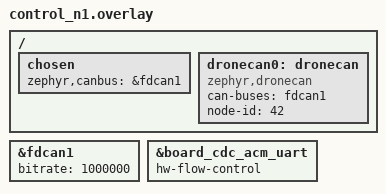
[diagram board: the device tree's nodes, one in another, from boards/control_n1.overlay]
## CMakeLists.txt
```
# SPDX-License-Identifier: Apache-2.0

cmake_minimum_required(VERSION 3.28.0)

# Use the module from this repository so the sample builds standalone.
list(APPEND ZEPHYR_EXTRA_MODULES ${CMAKE_CURRENT_LIST_DIR}/../..)

find_package(Zephyr REQUIRED HINTS $ENV{ZEPHYR_BASE})
project(dronecan_sample)

target_sources(app PRIVATE src/main.c)
```

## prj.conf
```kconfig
CONFIG_CAN=y
CONFIG_LOG=y
CONFIG_DRONECAN=y
CONFIG_DRONECAN_NODE_TABLE=y
CONFIG_DRONECAN_DNIA_SERVER=y
CONFIG_DRONECAN_LOG_LEVEL_DBG=y
```

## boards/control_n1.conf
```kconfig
# Console and logs on a USB CDC ACM port, using the USB device next stack.
# The board's own console is UART7, which needs a USB-serial adapter.
CONFIG_SERIAL=y
CONFIG_CONSOLE=y
CONFIG_UART_CONSOLE=y
CONFIG_UART_LINE_CTRL=y
CONFIG_USB_DEVICE_STACK_NEXT=y
CONFIG_USBD_CDC_ACM_CLASS=y
CONFIG_CDC_ACM_SERIAL_INITIALIZE_AT_BOOT=y

# The USB stack must not log through the port it is serving
CONFIG_USBD_LOG_LEVEL_OFF=y
CONFIG_USBD_CDC_ACM_LOG_LEVEL_OFF=y

# 3DR USB identifiers (same for all 3DR boards)
CONFIG_CDC_ACM_SERIAL_VID=0x26ac
CONFIG_CDC_ACM_SERIAL_PID=0x1186
CONFIG_CDC_ACM_SERIAL_MANUFACTURER_STRING="3DR"
CONFIG_CDC_ACM_SERIAL_PRODUCT_STRING="Control N1 DroneCAN"

CONFIG_MAIN_STACK_SIZE=2048
CONFIG_LOG_PROCESS_THREAD_STACK_SIZE=1024
```

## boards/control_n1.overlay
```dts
// Console and logs on a USB CDC ACM port (the board console is UART7)
#include <../boards/common/usb/cdc_acm_serial.dtsi>

/ {
	chosen {
		zephyr,canbus	= &fdcan1;
	};

	dronecan0: dronecan {
		compatible = "zephyr,dronecan";
		can-buses = <&fdcan1>;
		node-id = <42>;
		status = "okay";
	};
};

&fdcan1 {
	bitrate = <1000000>;
};

// The CDC ACM UART discards output while its USB packet is full.
// hw-flow-control makes it wait for a free packet, so no console output is lost.
&board_cdc_acm_uart {
	hw-flow-control;
};
```

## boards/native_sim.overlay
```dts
/ {
	dronecan0: dronecan {
		compatible = "zephyr,dronecan";
		can-buses = <&can_loopback0>;
		node-id = <42>;
		status = "okay";
	};
};
```

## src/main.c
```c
/*
 * Copyright (c) 2026 3DR, Inc.
 * SPDX-License-Identifier: Apache-2.0
 */

#include <zephyr/kernel.h>
#include <zephyr/device.h>
#include <zephyr/drivers/uart.h>
#include <zephyr/logging/log.h>

#include <dronecan.h>
#include <uavcan.protocol.NodeStatus.h>

LOG_MODULE_REGISTER(dronecan_sample, LOG_LEVEL_INF);

static const struct device *const dc = DEVICE_DT_GET(DT_NODELABEL(dronecan0));

#if DT_HAS_CHOSEN(zephyr_console) && DT_NODE_HAS_COMPAT(DT_CHOSEN(zephyr_console), zephyr_cdc_acm_uart)
#define CONSOLE_IS_CDC_ACM 1
#endif

// A USB console shows nothing until the host opens the port: wait for it (at most 15 s).
static void wait_for_console(void)
{
#ifdef CONSOLE_IS_CDC_ACM
	const struct device *console = DEVICE_DT_GET(DT_CHOSEN(zephyr_console));
	uint32_t dtr = 0;

	for (int i = 0; i < 150 && dtr == 0; i++) {
		uart_line_ctrl_get(console, UART_LINE_CTRL_DTR, &dtr);
		k_sleep(K_MSEC(100));
	}
	k_sleep(K_MSEC(200)); // let the terminal settle
#endif
}

static void show_stats(const char *when)
{
	struct dronecan_stats s;

	dronecan_get_stats(dc, &s);
	LOG_INF("%s: tx=%u tx_err=%u pool %u/%u (peak %u), IDs granted %u (last %u)", when, s.tx,
		s.tx_err, s.mem_current, s.mem_capacity, s.mem_peak, s.alloc_grant, s.last_grant_id);
}

static void show_nodes(void)
{
	struct dronecan_node_entry e;

	for (int id = 1; id < 128; id++) {
		if (dronecan_get_node(dc, id, &e) == 0 && e.active) {
			LOG_INF("node %d: up %u s, health %u, mode %u, vendor 0x%04x", id, e.uptime_sec,
				e.health, e.mode, e.vendor_status);
		}
	}
}

int main(void)
{
	static const struct dronecan_msg_desc node_status = {
		.id = UAVCAN_PROTOCOL_NODESTATUS_ID,
		.signature = UAVCAN_PROTOCOL_NODESTATUS_SIGNATURE,
		.max_size = UAVCAN_PROTOCOL_NODESTATUS_MAX_SIZE,
	};

	static const struct dronecan_msg_desc big = {.id = 1000, .signature = 0x1234, .max_size = 64};
	uint8_t payload[20] = {0};

	wait_for_console();
	LOG_INF("dronecan sample");

	if (!device_is_ready(dc)) {
		LOG_ERR("%s is not ready", dc->name);
		return -ENODEV;
	}

	LOG_INF("broadcast before start: %d", dronecan_broadcast(dc, &node_status,
		DRONECAN_PRIORITY_LOW, payload, 7));
	LOG_INF("stop before start: %d", dronecan_stop(dc));

	LOG_INF("start: %d", dronecan_start(dc));
	LOG_INF("second start: %d", dronecan_start(dc));
	LOG_INF("node id: %u", dronecan_get_node_id(dc));

	LOG_INF("broadcast NodeStatus-sized: %d",
		dronecan_broadcast(dc, &node_status, DRONECAN_PRIORITY_LOW, payload, 7));
	LOG_INF("broadcast 20 bytes: %d",
		dronecan_broadcast(dc, &big, DRONECAN_PRIORITY_LOW, payload, sizeof(payload)));
	LOG_INF("broadcast too long: %d",
		dronecan_broadcast(dc, &big, DRONECAN_PRIORITY_LOW, payload, 65));

	k_sleep(K_MSEC(300));
	show_stats("after traffic");

	LOG_INF("stop: %d", dronecan_stop(dc));
	LOG_INF("broadcast after stop: %d",
		dronecan_broadcast(dc, &node_status, DRONECAN_PRIORITY_LOW, payload, 7));
	LOG_INF("restart: %d", dronecan_start(dc));
	LOG_INF("broadcast after restart: %d",
		dronecan_broadcast(dc, &node_status, DRONECAN_PRIORITY_LOW, payload, 7));
	k_sleep(K_MSEC(300));
	show_stats("after restart");

	// NodeStatus keeps going out once a second: tx should grow by one each time.
	while (1) {
		show_stats("running");
		show_nodes();
		k_sleep(K_SECONDS(2));
	}

	return 0;
}
```
